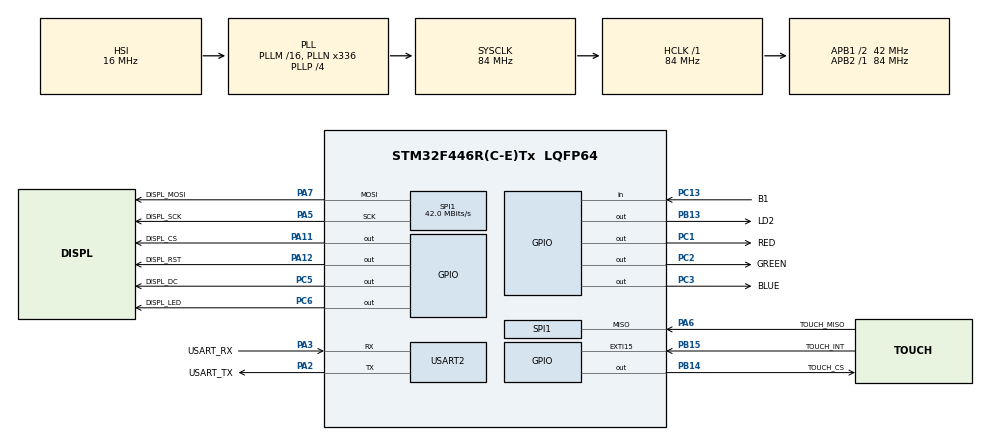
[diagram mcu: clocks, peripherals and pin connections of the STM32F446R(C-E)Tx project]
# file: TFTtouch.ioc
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Dma.Request0=SPI1_TX
Dma.SPI1_TX.0.Direction=DMA_MEMORY_TO_PERIPH
Dma.SPI1_TX.0.FIFOMode=DMA_FIFOMODE_DISABLE
Dma.SPI1_TX.0.Instance=DMA2_Stream3
Dma.SPI1_TX.0.MemDataAlignment=DMA_MDATAALIGN_BYTE
Dma.SPI1_TX.0.MemInc=DMA_MINC_ENABLE
Dma.SPI1_TX.0.Mode=DMA_NORMAL
Dma.SPI1_TX.0.PeriphDataAlignment=DMA_PDATAALIGN_BYTE
Dma.SPI1_TX.0.PeriphInc=DMA_PINC_DISABLE
Dma.SPI1_TX.0.Priority=DMA_PRIORITY_LOW
Mcu.Family=STM32F4
Mcu.Name=STM32F446R(C-E)Tx
Mcu.Package=LQFP64
NVIC.DMA2_Stream3_IRQn=true\:0\:0\:false\:false\:true\:false\:true\:true
NVIC.EXTI15_10_IRQn=true\:0\:0\:false\:false\:true\:true\:true\:true
NVIC.PriorityGroup=NVIC_PRIORITYGROUP_4
NVIC.SPI1_IRQn=true\:0\:0\:false\:false\:true\:true\:true\:true
PA11.GPIO_Label=DISPL_CS
PA11.Signal=GPIO_Output
PA12.GPIO_Label=DISPL_RST
PA12.Signal=GPIO_Output
PA13.GPIO_Label=TMS
PA13.Mode=Serial_Wire
PA13.Signal=SYS_JTMS-SWDIO
PA14.GPIO_Label=TCK
PA14.Mode=Serial_Wire
PA14.Signal=SYS_JTCK-SWCLK
PA2.GPIO_Label=USART_TX
PA2.Mode=Asynchronous
PA2.Signal=USART2_TX
PA3.GPIO_Label=USART_RX
PA3.Mode=Asynchronous
PA3.Signal=USART2_RX
PA5.GPIO_Label=DISPL_SCK
PA5.Mode=Full_Duplex_Master
PA5.Signal=SPI1_SCK
PA6.GPIO_Label=TOUCH_MISO
PA6.Mode=Full_Duplex_Master
PA6.Signal=SPI1_MISO
PA7.GPIO_Label=DISPL_MOSI
PA7.Mode=Full_Duplex_Master
PA7.Signal=SPI1_MOSI
PB13.GPIO_Label=LD2
PB13.GPIO_PuPd=GPIO_PULLUP
PB13.Signal=GPIO_Output
PB14.GPIO_Label=TOUCH_CS
PB14.Signal=GPIO_Output
PB15.GPIO_Label=TOUCH_INT
PB15.GPIO_ModeDefaultEXTI=GPIO_MODE_IT_FALLING
PB15.GPIO_PuPd=GPIO_PULLUP
PB15.Signal=GPXTI15
PB3.GPIO_Label=SWO
PB3.Signal=SYS_JTDO-SWO
PC1.GPIO_Label=RED
PC1.Signal=GPIO_Output
PC13.GPIO_Label=B1
PC13.GPIO_PuPd=GPIO_PULLDOWN
PC13.Signal=GPIO_Input
PC14-OSC32_IN.Mode=LSE-External-Oscillator
PC14-OSC32_IN.Signal=RCC_OSC32_IN
PC15-OSC32_OUT.Mode=LSE-External-Oscillator
PC15-OSC32_OUT.Signal=RCC_OSC32_OUT
PC2.GPIO_Label=GREEN
PC2.Signal=GPIO_Output
PC3.GPIO_Label=BLUE
PC3.Signal=GPIO_Output
PC5.GPIO_Label=DISPL_DC
PC5.Signal=GPIO_Output
PC6.GPIO_Label=DISPL_LED
PC6.Signal=GPIO_Output
PH0-OSC_IN.Mode=HSE-External-Oscillator
PH0-OSC_IN.Signal=RCC_OSC_IN
PH1-OSC_OUT.Mode=HSE-External-Oscillator
PH1-OSC_OUT.Signal=RCC_OSC_OUT
ProjectManager.HeapSize=0x200
ProjectManager.StackSize=0x400
ProjectManager.TargetToolchain=STM32CubeIDE
RCC.48MHZClocksFreq_Value=84000000
RCC.AHBFreq_Value=84000000
RCC.APB1CLKDivider=RCC_HCLK_DIV2
RCC.APB1Freq_Value=42000000
RCC.APB1TimFreq_Value=84000000
RCC.APB2Freq_Value=84000000
RCC.APB2TimFreq_Value=84000000
RCC.CortexFreq_Value=84000000
RCC.FLatency-AdvancedSettings=FLASH_LATENCY_2
RCC.HCLKFreq_Value=84000000
RCC.HSE_VALUE=8000000
RCC.HSI_VALUE=16000000
RCC.PLLN=336
RCC.PLLP=RCC_PLLP_DIV4
RCC.SYSCLKFreq_VALUE=84000000
RCC.SYSCLKSource=RCC_SYSCLKSOURCE_PLLCLK
RCC.USBFreq_Value=168000000
RCC.VCOOutputFreq_Value=336000000
SPI1.CRCCalculation=SPI_CRCCALCULATION_DISABLE
SPI1.CalculateBaudRate=42.0 MBits/s
SPI1.Direction=SPI_DIRECTION_2LINES
SPI1.Mode=SPI_MODE_MASTER
SPI1.VirtualType=VM_MASTER
STMicroelectronics.X-CUBE-TOUCHGFX.4.22.1.ApplicationCcGraphicsJjApplication=TouchGFXOoGenerator
STMicroelectronics.X-CUBE-TOUCHGFX.4.22.1.tgfx_buffering_strategy=Partial
STMicroelectronics.X-CUBE-TOUCHGFX.4.22.1.tgfx_custom_height=320
STMicroelectronics.X-CUBE-TOUCHGFX.4.22.1.tgfx_custom_width=240
STMicroelectronics.X-CUBE-TOUCHGFX.4.22.1_IsPackSelfContextualization=true
TIM3.AutoReloadPreload=TIM_AUTORELOAD_PRELOAD_ENABLE
TIM3.Period=50
TIM3.Prescaler=30000-1
USART2.VirtualMode=VM_ASYNC
VP_CRC_VS_CRC.Mode=CRC_Activate
VP_STMicroelectronics.X-CUBE-TOUCHGFX_VS_GraphicsJjApplication_4.22.1.Mode=GraphicsJjApplication
VP_TIM3_VS_ClockSourceINT.Mode=Internal
board=NUCLEO-F446RE

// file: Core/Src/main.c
/* USER CODE BEGIN Header */
/**
  ******************************************************************************
  * @file           : main.c
  * @brief          : Main program body
  ******************************************************************************
  * @attention
  *
  * Copyright (c) 2023 STMicroelectronics.
  * All rights reserved.
  *
  * This software is licensed under terms that can be found in the LICENSE file
  * in the root directory of this software component.
  * If no LICENSE file comes with this software, it is provided AS-IS.
  *
  ******************************************************************************
  */
/* USER CODE END Header */
#include "main.h"
#include "app_touchgfx.h"

CRC_HandleTypeDef hcrc;

SPI_HandleTypeDef hspi1;
DMA_HandleTypeDef hdma_spi1_tx;

TIM_HandleTypeDef htim3;

UART_HandleTypeDef huart2;

void SystemClock_Config(void);
static void MX_GPIO_Init(void);
static void MX_DMA_Init(void);
static void MX_USART2_UART_Init(void);
static void MX_SPI1_Init(void);
static void MX_CRC_Init(void);
static void MX_TIM3_Init(void);

int main(void)
{

  /* MCU Configuration--------------------------------------------------------*/

  /* Reset of all peripherals, Initializes the Flash interface and the Systick. */
  HAL_Init();

  /* Configure the system clock */
  SystemClock_Config();

  /* USER CODE BEGIN SysInit */

  // initialize the queue handler

  /* USER CODE END SysInit */

  /* Initialize all configured peripherals */
  MX_GPIO_Init();
  MX_DMA_Init();
  MX_USART2_UART_Init();
  MX_SPI1_Init();
  MX_CRC_Init();
  MX_TIM3_Init();
  MX_TouchGFX_Init();
  /* USER CODE BEGIN 2 */
  Displ_Init(Displ_Orientat_0);		// initialize the display and set the initial display orientation (here is orientaton: 0°) - THIS FUNCTION MUST PRECEED ANY OTHER DISPLAY FUNCTION CALL.
    touchgfxSignalVSync();		// asks TouchGFX to start initial display drawing
    Displ_BackLight('1');  			// initialize backlight and turn it on at init level

  /* USER CODE END 2 */

  /* Infinite loop */
  /* USER CODE BEGIN WHILE */
  while (1)
  {
	  touchgfxSignalVSync();		// asks TouchGFX to get events and redraw screen

    /* USER CODE END WHILE */

  MX_TouchGFX_Process();
  }
}

void SystemClock_Config(void)
{
  RCC_OscInitTypeDef RCC_OscInitStruct = {0};
  RCC_ClkInitTypeDef RCC_ClkInitStruct = {0};

  /** Configure the main internal regulator output voltage
  */
  __HAL_RCC_PWR_CLK_ENABLE();
  __HAL_PWR_VOLTAGESCALING_CONFIG(PWR_REGULATOR_VOLTAGE_SCALE3);

  /** Initializes the RCC Oscillators according to the specified parameters
  * in the RCC_OscInitTypeDef structure.
  */
  RCC_OscInitStruct.OscillatorType = RCC_OSCILLATORTYPE_HSI;
  RCC_OscInitStruct.HSIState = RCC_HSI_ON;
  RCC_OscInitStruct.HSICalibrationValue = RCC_HSICALIBRATION_DEFAULT;
  RCC_OscInitStruct.PLL.PLLState = RCC_PLL_ON;
  RCC_OscInitStruct.PLL.PLLSource = RCC_PLLSOURCE_HSI;
  RCC_OscInitStruct.PLL.PLLM = 16;
  RCC_OscInitStruct.PLL.PLLN = 336;
  RCC_OscInitStruct.PLL.PLLP = RCC_PLLP_DIV4;
  RCC_OscInitStruct.PLL.PLLQ = 2;
  RCC_OscInitStruct.PLL.PLLR = 2;
  if (HAL_RCC_OscConfig(&RCC_OscInitStruct) != HAL_OK)
  {
    Error_Handler();
  }

  /** Initializes the CPU, AHB and APB buses clocks
  */
  RCC_ClkInitStruct.ClockType = RCC_CLOCKTYPE_HCLK|RCC_CLOCKTYPE_SYSCLK
                              |RCC_CLOCKTYPE_PCLK1|RCC_CLOCKTYPE_PCLK2;
  RCC_ClkInitStruct.SYSCLKSource = RCC_SYSCLKSOURCE_PLLCLK;
  RCC_ClkInitStruct.AHBCLKDivider = RCC_SYSCLK_DIV1;
  RCC_ClkInitStruct.APB1CLKDivider = RCC_HCLK_DIV2;
  RCC_ClkInitStruct.APB2CLKDivider = RCC_HCLK_DIV1;

  if (HAL_RCC_ClockConfig(&RCC_ClkInitStruct, FLASH_LATENCY_2) != HAL_OK)
  {
    Error_Handler();
  }
}

static void MX_CRC_Init(void)
{

  hcrc.Instance = CRC;
  if (HAL_CRC_Init(&hcrc) != HAL_OK)
  {
    Error_Handler();
  }

}

static void MX_SPI1_Init(void)
{

  /* SPI1 parameter configuration*/
  hspi1.Instance = SPI1;
  hspi1.Init.Mode = SPI_MODE_MASTER;
  hspi1.Init.Direction = SPI_DIRECTION_2LINES;
  hspi1.Init.DataSize = SPI_DATASIZE_8BIT;
  hspi1.Init.CLKPolarity = SPI_POLARITY_LOW;
  hspi1.Init.CLKPhase = SPI_PHASE_1EDGE;
  hspi1.Init.NSS = SPI_NSS_SOFT;
  hspi1.Init.BaudRatePrescaler = SPI_BAUDRATEPRESCALER_2;
  hspi1.Init.FirstBit = SPI_FIRSTBIT_MSB;
  hspi1.Init.TIMode = SPI_TIMODE_DISABLE;
  hspi1.Init.CRCCalculation = SPI_CRCCALCULATION_DISABLE;
  hspi1.Init.CRCPolynomial = 10;
  if (HAL_SPI_Init(&hspi1) != HAL_OK)
  {
    Error_Handler();
  }

}

static void MX_TIM3_Init(void)
{

  TIM_ClockConfigTypeDef sClockSourceConfig = {0};
  TIM_MasterConfigTypeDef sMasterConfig = {0};

  htim3.Instance = TIM3;
  htim3.Init.Prescaler = 30000-1;
  htim3.Init.CounterMode = TIM_COUNTERMODE_UP;
  htim3.Init.Period = 50;
  htim3.Init.ClockDivision = TIM_CLOCKDIVISION_DIV1;
  htim3.Init.AutoReloadPreload = TIM_AUTORELOAD_PRELOAD_ENABLE;
  if (HAL_TIM_Base_Init(&htim3) != HAL_OK)
  {
    Error_Handler();
  }
  sClockSourceConfig.ClockSource = TIM_CLOCKSOURCE_INTERNAL;
  if (HAL_TIM_ConfigClockSource(&htim3, &sClockSourceConfig) != HAL_OK)
  {
    Error_Handler();
  }
  sMasterConfig.MasterOutputTrigger = TIM_TRGO_RESET;
  sMasterConfig.MasterSlaveMode = TIM_MASTERSLAVEMODE_DISABLE;
  if (HAL_TIMEx_MasterConfigSynchronization(&htim3, &sMasterConfig) != HAL_OK)
  {
    Error_Handler();
  }

}

static void MX_USART2_UART_Init(void)
{

  huart2.Instance = USART2;
  huart2.Init.BaudRate = 115200;
  huart2.Init.WordLength = UART_WORDLENGTH_8B;
  huart2.Init.StopBits = UART_STOPBITS_1;
  huart2.Init.Parity = UART_PARITY_NONE;
  huart2.Init.Mode = UART_MODE_TX_RX;
  huart2.Init.HwFlowCtl = UART_HWCONTROL_NONE;
  huart2.Init.OverSampling = UART_OVERSAMPLING_16;
  if (HAL_UART_Init(&huart2) != HAL_OK)
  {
    Error_Handler();
  }

}

static void MX_DMA_Init(void)
{

  /* DMA controller clock enable */
  __HAL_RCC_DMA2_CLK_ENABLE();

  /* DMA interrupt init */
  /* DMA2_Stream3_IRQn interrupt configuration */
  HAL_NVIC_SetPriority(DMA2_Stream3_IRQn, 0, 0);
  HAL_NVIC_EnableIRQ(DMA2_Stream3_IRQn);

}

static void MX_GPIO_Init(void)
{
  GPIO_InitTypeDef GPIO_InitStruct = {0};

  /* GPIO Ports Clock Enable */
  __HAL_RCC_GPIOC_CLK_ENABLE();
  __HAL_RCC_GPIOH_CLK_ENABLE();
  __HAL_RCC_GPIOA_CLK_ENABLE();
  __HAL_RCC_GPIOB_CLK_ENABLE();

  /*Configure GPIO pin Output Level */
  HAL_GPIO_WritePin(GPIOC, RED_Pin|GREEN_Pin|BLUE_Pin|DISPL_DC_Pin
                          |DISPL_LED_Pin, GPIO_PIN_RESET);

  /*Configure GPIO pin Output Level */
  HAL_GPIO_WritePin(GPIOB, LD2_Pin|TOUCH_CS_Pin, GPIO_PIN_RESET);

  /*Configure GPIO pin Output Level */
  HAL_GPIO_WritePin(GPIOA, DISPL_CS_Pin|DISPL_RST_Pin, GPIO_PIN_RESET);

  /*Configure GPIO pin : B1_Pin */
  GPIO_InitStruct.Pin = B1_Pin;
  GPIO_InitStruct.Mode = GPIO_MODE_INPUT;
  GPIO_InitStruct.Pull = GPIO_PULLDOWN;
  HAL_GPIO_Init(B1_GPIO_Port, &GPIO_InitStruct);

  /*Configure GPIO pins : RED_Pin GREEN_Pin BLUE_Pin DISPL_DC_Pin
                           DISPL_LED_Pin */
  GPIO_InitStruct.Pin = RED_Pin|GREEN_Pin|BLUE_Pin|DISPL_DC_Pin
                          |DISPL_LED_Pin;
  GPIO_InitStruct.Mode = GPIO_MODE_OUTPUT_PP;
  GPIO_InitStruct.Pull = GPIO_NOPULL;
  GPIO_InitStruct.Speed = GPIO_SPEED_FREQ_LOW;
  HAL_GPIO_Init(GPIOC, &GPIO_InitStruct);

  /*Configure GPIO pin : LD2_Pin */
  GPIO_InitStruct.Pin = LD2_Pin;
  GPIO_InitStruct.Mode = GPIO_MODE_OUTPUT_PP;
  GPIO_InitStruct.Pull = GPIO_PULLUP;
  GPIO_InitStruct.Speed = GPIO_SPEED_FREQ_LOW;
  HAL_GPIO_Init(LD2_GPIO_Port, &GPIO_InitStruct);

  /*Configure GPIO pin : TOUCH_CS_Pin */
  GPIO_InitStruct.Pin = TOUCH_CS_Pin;
  GPIO_InitStruct.Mode = GPIO_MODE_OUTPUT_PP;
  GPIO_InitStruct.Pull = GPIO_NOPULL;
  GPIO_InitStruct.Speed = GPIO_SPEED_FREQ_LOW;
  HAL_GPIO_Init(TOUCH_CS_GPIO_Port, &GPIO_InitStruct);

  /*Configure GPIO pin : TOUCH_INT_Pin */
  GPIO_InitStruct.Pin = TOUCH_INT_Pin;
  GPIO_InitStruct.Mode = GPIO_MODE_IT_FALLING;
  GPIO_InitStruct.Pull = GPIO_PULLUP;
  HAL_GPIO_Init(TOUCH_INT_GPIO_Port, &GPIO_InitStruct);

  /*Configure GPIO pins : DISPL_CS_Pin DISPL_RST_Pin */
  GPIO_InitStruct.Pin = DISPL_CS_Pin|DISPL_RST_Pin;
  GPIO_InitStruct.Mode = GPIO_MODE_OUTPUT_PP;
  GPIO_InitStruct.Pull = GPIO_NOPULL;
  GPIO_InitStruct.Speed = GPIO_SPEED_FREQ_LOW;
  HAL_GPIO_Init(GPIOA, &GPIO_InitStruct);

  /* EXTI interrupt init*/
  HAL_NVIC_SetPriority(EXTI15_10_IRQn, 0, 0);
  HAL_NVIC_EnableIRQ(EXTI15_10_IRQn);

}

void Error_Handler(void)
{
  __disable_irq();
  while (1)
  {
  }
}
